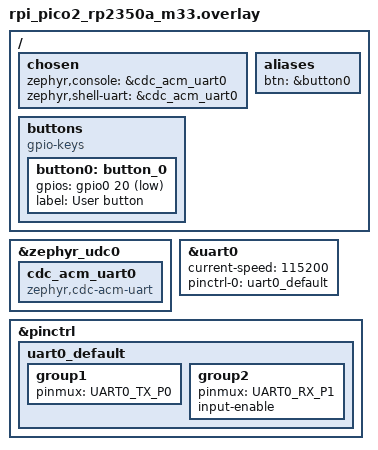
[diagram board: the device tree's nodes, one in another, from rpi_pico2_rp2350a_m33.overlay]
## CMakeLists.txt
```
# See anatomy of a CMake file here: https://docs.zephyrproject.org/latest/develop/application/index.html#creating-an-application-by-hand
cmake_minimum_required(VERSION 3.13.1)

# Sets the variable BOARD, which tells build system which board to select if no board is specified
set(BOARD rpi_pico2/rp2350a/m33)

# Pulls in Zephyr build system
find_package(Zephyr)

# Defines application
project(Sender)

# Collects and adds sources to app target
file(GLOB SRC_FILES "src/*c")
target_sources(app PRIVATE ${SRC_FILES})
```

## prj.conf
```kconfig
CONFIG_SERIAL=y
CONFIG_CONSOLE=y
CONFIG_UART_CONSOLE=y
CONFIG_STDOUT_CONSOLE=y
CONFIG_UART_LINE_CTRL=y

CONFIG_USB_DEVICE_STACK_NEXT=y
CONFIG_CDC_ACM_SERIAL_INITIALIZE_AT_BOOT=y
CONFIG_CDC_ACM_SERIAL_PID=0x0004
CONFIG_CDC_ACM_SERIAL_PRODUCT_STRING="USBD console sample"
```

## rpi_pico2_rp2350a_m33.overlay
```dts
/ {
    chosen {
        zephyr,console = &cdc_acm_uart0;
        zephyr,shell-uart = &cdc_acm_uart0;
    };

    /* ── Button alias ──────────────────────────────────────────── */
    aliases {
        btn = &button0;
    };

    buttons {
        compatible = "gpio-keys";

        button0: button_0 {
            gpios = <&gpio0 20 (GPIO_ACTIVE_LOW | GPIO_PULL_UP)>;
            label = "User button";
        };
    };
};

&zephyr_udc0 {
    cdc_acm_uart0: cdc_acm_uart0 {
        compatible = "zephyr,cdc-acm-uart";
    };
};

&uart0 {
    status = "okay";
    current-speed = <115200>;
    pinctrl-0 = <&uart0_default>;
    pinctrl-names = "default";
};

&pinctrl {
    uart0_default: uart0_default {
        group1 {
            pinmux = <UART0_TX_P0>;
        };
        group2 {
            pinmux = <UART0_RX_P1>;
            input-enable;
        };
    };
};
```

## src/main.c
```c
#include <zephyr/kernel.h>
#include <zephyr/drivers/uart.h>
#include <zephyr/sys/printk.h>
#include <zephyr/drivers/gpio.h>
#include <zephyr/device.h>
#include <zephyr/sys/util.h>

#define STACK_SIZE 500
#define UART_NODE  DT_NODELABEL(uart0)
#define BTN_NODE   DT_ALIAS(btn)

/* Semaphore: ISR signals button_task */
K_SEM_DEFINE(btn_sem, 0, 1);

static const struct device *uart_dev = DEVICE_DT_GET(UART_NODE);
static const struct gpio_dt_spec btn = GPIO_DT_SPEC_GET(BTN_NODE, gpios);

static struct gpio_callback btn_cb_data;

static void button_isr(const struct device *dev,
                       struct gpio_callback *cb,
                       uint32_t pins)
{
    ARG_UNUSED(dev);
    ARG_UNUSED(cb);
    ARG_UNUSED(pins);
    /* k_sem_give is ISR-safe */
    k_sem_give(&btn_sem);
}

/* Helper: send a string over UART */
static void uart_send(const char *msg)
{
    for (int i = 0; msg[i] != '\0'; i++) {
        uart_poll_out(uart_dev, msg[i]);
    }
}

/* wakes on semaphore, sends a message */
void button_task(void *p1, void *p2, void *p3)
{
    ARG_UNUSED(p1);
    ARG_UNUSED(p2);
    ARG_UNUSED(p3);

    for (;;) {
        k_sem_take(&btn_sem, K_FOREVER);   /* blocks until ISR fires */
        uart_send("button pressed!\n");
        printk("Button event sent\n");
    }
}

K_THREAD_DEFINE(button_tid, STACK_SIZE,
                button_task, NULL, NULL, NULL,
                1, 0, 0);

/* configure GPIO interrupt, then keep sending*/
int main(void)
{
    /* Configures button */
    gpio_pin_configure_dt(&btn, GPIO_INPUT);

    /* Registers interrupt on edge to active level */
    gpio_pin_interrupt_configure_dt(&btn, GPIO_INT_EDGE_TO_ACTIVE);

    /* Initializes callback struct with ISR and the pins on which ISR should trigger  */
    gpio_init_callback(&btn_cb_data, button_isr, BIT(btn.pin));

    /* Adds ISR callback to the device */
    gpio_add_callback_dt(&btn, &btn_cb_data);

    printk("Sender started on UART0\n");

    while (1) {
        uart_send("hello from sender\n");
        printk("Message sent\n");
        k_msleep(1000);
    }
}
```
